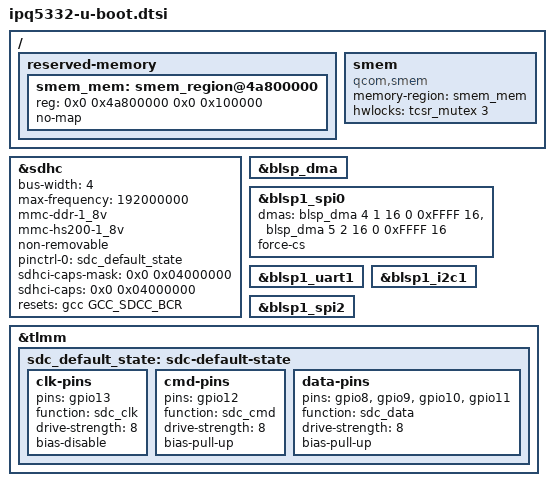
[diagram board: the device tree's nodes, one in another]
// SPDX-License-Identifier: GPL-2.0+
/*
 * Copyright (c) Qualcomm Technologies, Inc. and/or its subsidiaries.
 */
/ {

	reserved-memory {

		/delete-node/ smem;
		smem_mem: smem_region@4a800000 {
			reg = <0x0 0x4a800000 0x0 0x100000>;
			no-map;
		};
	};

	smem {
		compatible = "qcom,smem";
		memory-region = <&smem_mem>;
		hwlocks = <&tcsr_mutex 3>;
	};
};

&sdhc {
	bus-width = <4>;
	max-frequency = <192000000>;
	mmc-ddr-1_8v;
	mmc-hs200-1_8v;
	non-removable;
	pinctrl-0 = <&sdc_default_state>;
	pinctrl-names = "default";
	status = "okay";
	sdhci-caps-mask = <0x0 0x04000000>;
	sdhci-caps = <0x0 0x04000000>;
	resets = <&gcc GCC_SDCC_BCR>;
	reset-names = "bcr_rst";
};

&blsp_dma {
	#dma-cells = <6>;
	status = "okay";
};

&blsp1_spi0 {
	dmas = <&blsp_dma 4 1 16 0 0xFFFF 16>,
	       <&blsp_dma 5 2 16 0 0xFFFF 16>;
	force-cs;
	status = "okay";
};

&blsp1_uart1 {
	/delete-property/ dmas;
	/delete-property/ dma-names;
};

&blsp1_i2c1 {
	/delete-property/ dmas;
	/delete-property/ dma-names;
};

&blsp1_spi2 {
	/delete-property/ dmas;
	/delete-property/ dma-names;
};

&tlmm {
	sdc_default_state: sdc-default-state {
		clk-pins {
			pins = "gpio13";
			function = "sdc_clk";
			drive-strength = <8>;
			bias-disable;
		};

		cmd-pins {
			pins = "gpio12";
			function = "sdc_cmd";
			drive-strength = <8>;
			bias-pull-up;
		};

		data-pins {
			pins = "gpio8", "gpio9", "gpio10", "gpio11";
			function = "sdc_data";
			drive-strength = <8>;
			bias-pull-up;
		};
	};
};
